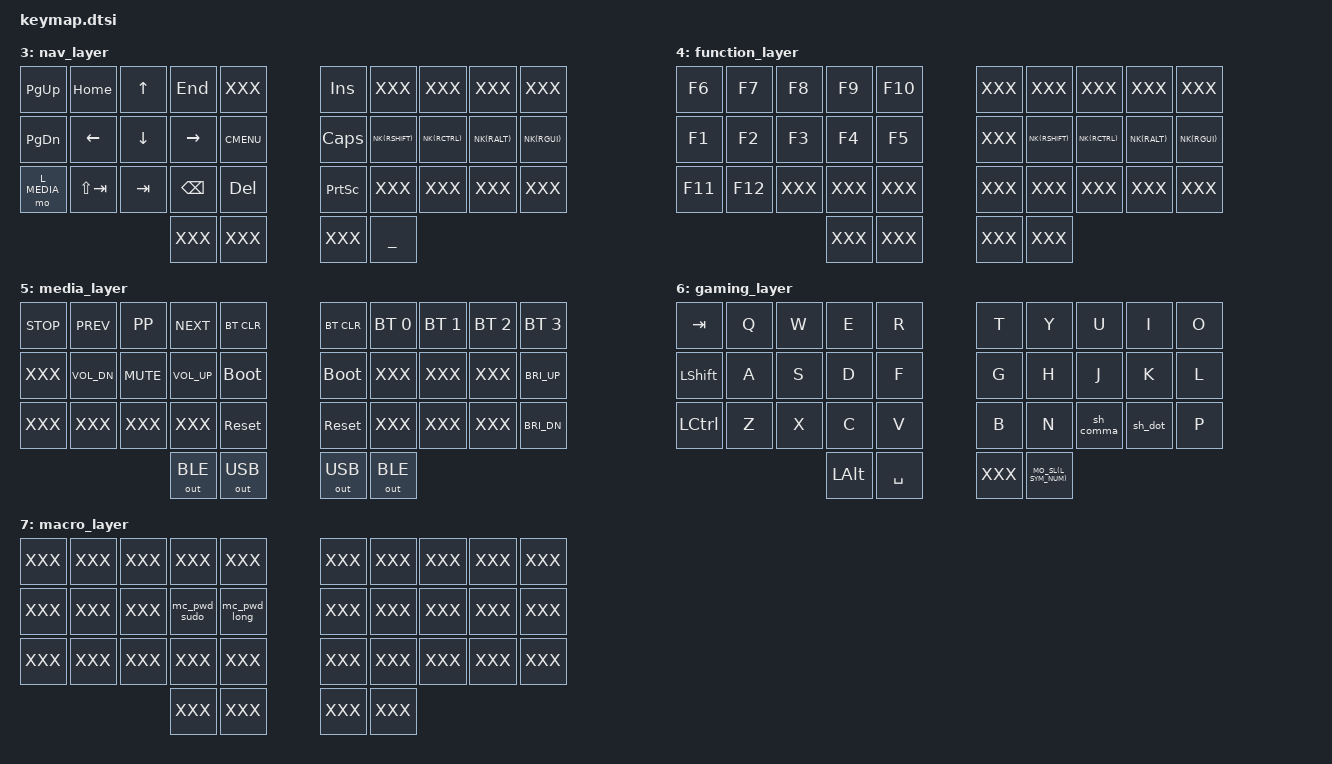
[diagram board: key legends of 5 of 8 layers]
/ {
  keymap {
    compatible = "zmk,keymap";
    colemak_layer {
      bindings = <
// ╭─────────────┬─────────────┬─────────────┬─────────────┬─────────────╮   ╭─────────────┬─────────────┬─────────────┬─────────────┬─────────────╮
     &kp Q         &kp W         &kp F         &kp P         &kp B             &kp J         &kp L         &kp U         &kp Y         &kp SQT
// ├─────────────┼─────────────┼─────────────┼─────────────┼─────────────┤   ├─────────────┼─────────────┼─────────────┼─────────────┼─────────────┤
     HRML(A,       R,            S,            T)            &kp G             &kp M         HRMR(N,       E,            I,            O)
// ├─────────────┼─────────────┼─────────────┼─────────────┼─────────────┤   ├─────────────┼─────────────┼─────────────┼─────────────┼─────────────┤
     MO_MACRO(Z)   &kp X         &kp C         &kp D         &kp V             &kp K         &kp H         &sh_comma     &sh_dot       &sh_slash
// ╰─────────────┴─────────────┴─────────────┼─────────────┼─────────────┤   ├─────────────┼─────────────┼─────────────┴─────────────┴─────────────╯
                                              LT_REPEAT(L_NAV) &kp SPACE       MAGIC_SHIFT   MO_SL(L_SYM_NUM)
//                                           ╰─────────────┴─────────────╯   ╰─────────────┴─────────────╯
//                                                     TODO: &lt BOH SPACE
//                                                     TODO: FUNCT on tap-tap-hold?
      >;
    };
    querty_layer {
      bindings = <
// ╭─────────────┬─────────────┬─────────────┬─────────────┬─────────────╮   ╭─────────────┬─────────────┬─────────────┬─────────────┬─────────────╮
     &kp Q         &kp W         &kp E         &kp R         &kp T             &kp Y         &kp U         &kp I         &kp O         &kp P
// ├─────────────┼─────────────┼─────────────┼─────────────┼─────────────┤   ├─────────────┼─────────────┼─────────────┼─────────────┼─────────────┤
     HRML(A,       S,            D,            F)            &kp G             &kp H         HRMR(J,       K,            L,            SEMICOLON)
// ├─────────────┼─────────────┼─────────────┼─────────────┼─────────────┤   ├─────────────┼─────────────┼─────────────┼─────────────┼─────────────┤
     MO_MACRO(Z)   &kp X         &kp C         &kp V         &kp B             &kp N         &kp M         &sh_comma     &sh_dot       &sh_slash
// ╰─────────────┴─────────────┴─────────────┼─────────────┼─────────────┤   ├─────────────┼─────────────┼─────────────┴─────────────┴─────────────╯
                                               ___           ___               ___           ___
//                                           ╰─────────────┴─────────────╯   ╰─────────────┴─────────────╯
      >;
    };
    sym_num_layer {
      bindings = <
// ╭─────────────┬─────────────┬─────────────┬─────────────┬─────────────╮   ╭─────────────┬─────────────┬─────────────┬─────────────┬─────────────╮
     &mc_excl      &mc_at        &mc_hash      &mc_dllr      &mc_prcnt         &mc_caret     &mc_amps      &mc_star      &mc_qmark     &mc_grave
// ├─────────────┼─────────────┼─────────────┼─────────────┼─────────────┤   ├─────────────┼─────────────┼─────────────┼─────────────┼─────────────┤
     HRML(N1,      N2,           N3,           N4)           &kp N5            &kp N6        HRMR(N7,      N8,           N9,           N0)
// ├─────────────┼─────────────┼─────────────┼─────────────┼─────────────┤   ├─────────────┼─────────────┼─────────────┼─────────────┼─────────────┤
     XXX           XXX           &mc_minus     &mc_plus      &mc_tilde         &mc_pipe      &mc_equal     &mc_lt        &mc_gt        &mc_under
// ╰─────────────┴─────────────┴─────────────┼─────────────┼─────────────┤   ├─────────────┼─────────────┼─────────────┴─────────────┴─────────────╯
                                               ___           ___               ___           ___
//                                           ╰─────────────┴─────────────╯   ╰─────────────┴─────────────╯
      >;
    };
    nav_layer {
      bindings = <
// ╭─────────────┬─────────────┬─────────────┬─────────────┬─────────────╮   ╭─────────────┬─────────────┬─────────────┬─────────────┬─────────────╮
     &kp PG_UP     &kp HOME      &kp UP        &kp END       XXX               &kp INS       XXX           XXX           XXX           XXX
// ├─────────────┼─────────────┼─────────────┼─────────────┼─────────────┤   ├─────────────┼─────────────┼─────────────┼─────────────┼─────────────┤
     &kp PG_DN     &kp LEFT      &kp DOWN      &kp RIGHT     &kp K_CMENU       &kp CAPS      NK(RSHIFT)    NK(RCTRL)     NK(RALT)      NK(RGUI)
// ├─────────────┼─────────────┼─────────────┼─────────────┼─────────────┤   ├─────────────┼─────────────┼─────────────┼─────────────┼─────────────┤
     &mo L_MEDIA   &kp LS(TAB)   &kp TAB       &kp BSPC      &kp DEL           &kp PSCRN     XXX           XXX           XXX           XXX
// ╰─────────────┴─────────────┴─────────────┼─────────────┼─────────────┤   ├─────────────┼─────────────┼─────────────┴─────────────┴─────────────╯
                                               XXX           XXX               XXX           ___ 
//                                           ╰─────────────┴─────────────╯   ╰─────────────┴─────────────╯
      >;
    };
    function_layer {
      bindings = <
// ╭─────────────┬─────────────┬─────────────┬─────────────┬─────────────╮   ╭─────────────┬─────────────┬─────────────┬─────────────┬─────────────╮
     &kp F6        &kp F7        &kp F8        &kp F9        &kp F10           XXX           XXX           XXX           XXX           XXX
// ├─────────────┼─────────────┼─────────────┼─────────────┼─────────────┤   ├─────────────┼─────────────┼─────────────┼─────────────┼─────────────┤
     &kp F1        &kp F2        &kp F3        &kp F4        &kp F5            XXX           NK(RSHIFT)    NK(RCTRL)     NK(RALT)      NK(RGUI)
// ├─────────────┼─────────────┼─────────────┼─────────────┼─────────────┤   ├─────────────┼─────────────┼─────────────┼─────────────┼─────────────┤
     &kp F11       &kp F12       XXX           XXX           XXX               XXX           XXX           XXX           XXX           XXX
// ╰─────────────┴─────────────┴─────────────┼─────────────┼─────────────┤   ├─────────────┼─────────────┼─────────────┴─────────────┴─────────────╯
                                               XXX           XXX               XXX           XXX
//                                           ╰─────────────┴─────────────╯   ╰─────────────┴─────────────╯
      >;
    };
    media_layer {
      bindings = <
// ╭─────────────┬─────────────┬─────────────┬─────────────┬─────────────╮   ╭─────────────┬─────────────┬─────────────┬─────────────┬─────────────╮
     &kp K_STOP    &kp K_PREV    &kp K_PP      &kp K_NEXT    &bt BT_CLR        &bt BT_CLR    &bt BT_SEL 0  &bt BT_SEL 1  &bt BT_SEL 2  &bt BT_SEL 3 
// ├─────────────┼─────────────┼─────────────┼─────────────┼─────────────┤   ├─────────────┼─────────────┼─────────────┼─────────────┼─────────────┤
     XXX           &kp K_VOL_DN  &kp K_MUTE    &kp K_VOL_UP  &bootloader       &bootloader   XXX           XXX           XXX           &kp C_BRI_UP
// ├─────────────┼─────────────┼─────────────┼─────────────┼─────────────┤   ├─────────────┼─────────────┼─────────────┼─────────────┼─────────────┤
     XXX           XXX           XXX           XXX           &sys_reset        &sys_reset    XXX           XXX           XXX           &kp C_BRI_DN
// ╰─────────────┴─────────────┴─────────────┼─────────────┼─────────────┤   ├─────────────┼─────────────┼─────────────┴─────────────┴─────────────╯
                                               &out OUT_BLE  &out OUT_USB      &out OUT_USB  &out OUT_BLE
//                                           ╰─────────────┴─────────────╯   ╰─────────────┴─────────────╯
      >;
    };
    gaming_layer {
      bindings = <
// ╭─────────────┬─────────────┬─────────────┬─────────────┬─────────────╮   ╭─────────────┬─────────────┬─────────────┬─────────────┬─────────────╮
     &kp TAB       &kp Q         &kp W         &kp E         &kp R             &kp T         &kp Y         &kp U         &kp I         &kp O
// ├─────────────┼─────────────┼─────────────┼─────────────┼─────────────┤   ├─────────────┼─────────────┼─────────────┼─────────────┼─────────────┤
     &kp LSHIFT    &kp A         &kp S         &kp D         &kp F             &kp G         &kp H         &kp J         &kp K         &kp L
// ├─────────────┼─────────────┼─────────────┼─────────────┼─────────────┤   ├─────────────┼─────────────┼─────────────┼─────────────┼─────────────┤
     &kp LCTRL     &kp Z         &kp X         &kp C         &kp V             &kp B         &kp N         &sh_comma     &sh_dot       &kp P
// ╰─────────────┴─────────────┴─────────────┼─────────────┼─────────────┤   ├─────────────┼─────────────┼─────────────┴─────────────┴─────────────╯
                                               &kp LALT      &kp SPACE         XXX           MO_SL(L_SYM_NUM)
//                                           ╰─────────────┴─────────────╯   ╰─────────────┴─────────────╯
      >;
    };
    macro_layer {
      bindings = <
// ╭─────────────┬─────────────┬─────────────┬─────────────┬─────────────╮   ╭─────────────┬─────────────┬─────────────┬─────────────┬─────────────╮
     XXX           XXX           XXX           XXX           XXX               XXX           XXX           XXX           XXX           XXX
// ├─────────────┼─────────────┼─────────────┼─────────────┼─────────────┤   ├─────────────┼─────────────┼─────────────┼─────────────┼─────────────┤
     XXX           XXX           XXX           &mc_pwd_sudo  &mc_pwd_long      XXX           XXX           XXX           XXX           XXX
// ├─────────────┼─────────────┼─────────────┼─────────────┼─────────────┤   ├─────────────┼─────────────┼─────────────┼─────────────┼─────────────┤
     XXX           XXX           XXX           XXX           XXX               XXX           XXX           XXX           XXX           XXX
// ╰─────────────┴─────────────┴─────────────┼─────────────┼─────────────┤   ├─────────────┼─────────────┼─────────────┴─────────────┴─────────────╯
                                               XXX           XXX               XXX           XXX
//                                           ╰─────────────┴─────────────╯   ╰─────────────┴─────────────╯
      >;
    };
//    mouse_layer {
//      bindings = <
//// ╭─────────────┬─────────────┬─────────────┬─────────────┬─────────────╮   ╭─────────────┬─────────────┬─────────────┬─────────────┬─────────────╮
//     &kp LALT    &msc SCRL_DOWN &mmv MOVE_UP   &msc SCRL_UP  XXX               XXX           XXX           XXX           XXX           XXX
//// ├─────────────┼─────────────┼─────────────┼─────────────┼─────────────┤   ├─────────────┼─────────────┼─────────────┼─────────────┼─────────────┤
//     &kp LSHIFT &mmv MOVE_LEFT &mmv MOVE_DOWN &mmv MOVE_RIGHT &mkp MB4         XXX           XXX           XXX           XXX           XXX
//// ├─────────────┼─────────────┼─────────────┼─────────────┼─────────────┤   ├─────────────┼─────────────┼─────────────┼─────────────┼─────────────┤
//     &kp LCTRL   &msc SCRL_LEFT  &mkp MCLK   &msc SCRL_RIGHT &mkp MB5          XXX           XXX           XXX           XXX           XXX
//// ╰─────────────┴─────────────┴─────────────┼─────────────┼─────────────┤   ├─────────────┼─────────────┼─────────────┴─────────────┴─────────────╯
//                                               &mkp RCLK     &mkp LCLK         XXX           XXX
////                                           ╰─────────────┴─────────────╯   ╰─────────────┴─────────────╯
//      >;
//    };
  };
};
